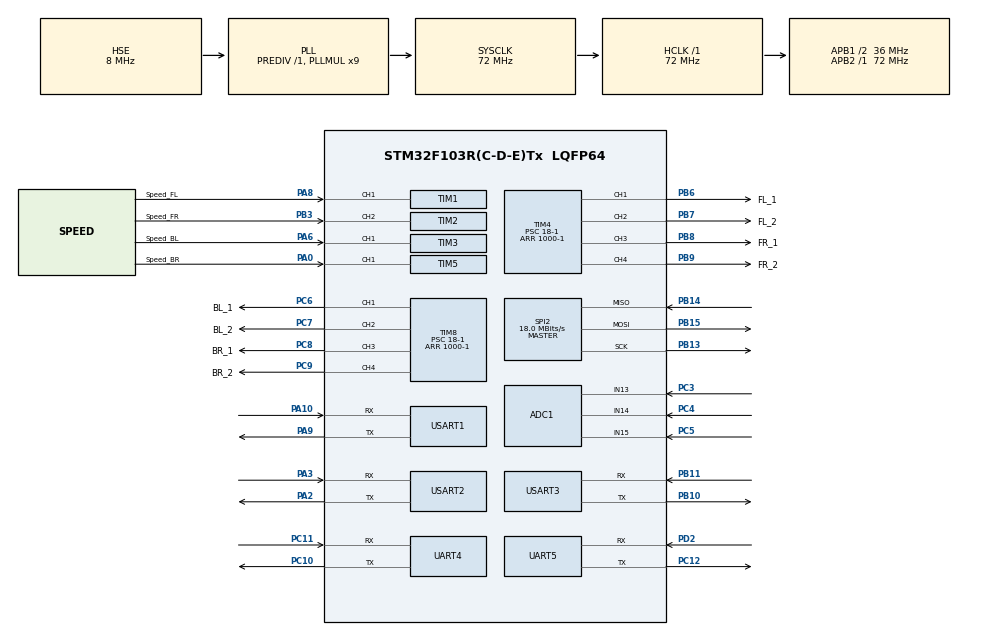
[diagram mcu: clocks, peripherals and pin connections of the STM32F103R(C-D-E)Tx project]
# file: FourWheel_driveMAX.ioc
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ADC1.Channel-0\#ChannelRegularConversion=ADC_CHANNEL_13
ADC1.NbrOfConversionFlag=1
ADC1.Rank-0\#ChannelRegularConversion=1
ADC1.SamplingTime-0\#ChannelRegularConversion=ADC_SAMPLETIME_1CYCLE_5
ADC1.master=1
Dma.Request0=UART4_TX
Dma.Request1=USART3_TX
Dma.Request2=USART2_TX
Dma.Request3=USART1_TX
Dma.UART4_TX.0.Direction=DMA_MEMORY_TO_PERIPH
Dma.UART4_TX.0.Instance=DMA2_Channel5
Dma.UART4_TX.0.MemDataAlignment=DMA_MDATAALIGN_BYTE
Dma.UART4_TX.0.MemInc=DMA_MINC_ENABLE
Dma.UART4_TX.0.Mode=DMA_NORMAL
Dma.UART4_TX.0.PeriphDataAlignment=DMA_PDATAALIGN_BYTE
Dma.UART4_TX.0.PeriphInc=DMA_PINC_DISABLE
Dma.UART4_TX.0.Priority=DMA_PRIORITY_LOW
Dma.USART1_TX.3.Direction=DMA_MEMORY_TO_PERIPH
Dma.USART1_TX.3.Instance=DMA1_Channel4
Dma.USART1_TX.3.MemDataAlignment=DMA_MDATAALIGN_BYTE
Dma.USART1_TX.3.MemInc=DMA_MINC_ENABLE
Dma.USART1_TX.3.Mode=DMA_NORMAL
Dma.USART1_TX.3.PeriphDataAlignment=DMA_PDATAALIGN_BYTE
Dma.USART1_TX.3.PeriphInc=DMA_PINC_DISABLE
Dma.USART1_TX.3.Priority=DMA_PRIORITY_LOW
Dma.USART2_TX.2.Direction=DMA_MEMORY_TO_PERIPH
Dma.USART2_TX.2.Instance=DMA1_Channel7
Dma.USART2_TX.2.MemDataAlignment=DMA_MDATAALIGN_BYTE
Dma.USART2_TX.2.MemInc=DMA_MINC_ENABLE
Dma.USART2_TX.2.Mode=DMA_NORMAL
Dma.USART2_TX.2.PeriphDataAlignment=DMA_PDATAALIGN_BYTE
Dma.USART2_TX.2.PeriphInc=DMA_PINC_DISABLE
Dma.USART2_TX.2.Priority=DMA_PRIORITY_LOW
Dma.USART3_TX.1.Direction=DMA_MEMORY_TO_PERIPH
Dma.USART3_TX.1.Instance=DMA1_Channel2
Dma.USART3_TX.1.MemDataAlignment=DMA_MDATAALIGN_BYTE
Dma.USART3_TX.1.MemInc=DMA_MINC_ENABLE
Dma.USART3_TX.1.Mode=DMA_NORMAL
Dma.USART3_TX.1.PeriphDataAlignment=DMA_PDATAALIGN_BYTE
Dma.USART3_TX.1.PeriphInc=DMA_PINC_DISABLE
Dma.USART3_TX.1.Priority=DMA_PRIORITY_LOW
IWDG.Prescaler=IWDG_PRESCALER_64
IWDG.Reload=2500
Mcu.Family=STM32F1
Mcu.Name=STM32F103R(C-D-E)Tx
Mcu.Package=LQFP64
NVIC.DMA1_Channel2_IRQn=true\:0\:0\:false\:false\:true\:false\:true
NVIC.DMA1_Channel4_IRQn=true\:0\:0\:false\:false\:true\:false\:true
NVIC.DMA1_Channel7_IRQn=true\:0\:0\:false\:false\:true\:false\:true
NVIC.DMA2_Channel4_5_IRQn=true\:0\:0\:false\:false\:true\:false\:true
NVIC.PriorityGroup=NVIC_PRIORITYGROUP_4
NVIC.TIM1_BRK_IRQn=true\:0\:0\:false\:false\:true\:true\:true
NVIC.TIM1_CC_IRQn=true\:0\:0\:false\:false\:true\:true\:true
NVIC.TIM1_TRG_COM_IRQn=true\:0\:0\:false\:false\:true\:true\:true
NVIC.TIM1_UP_IRQn=true\:0\:0\:false\:false\:true\:true\:true
NVIC.TIM2_IRQn=true\:0\:0\:false\:false\:true\:true\:true
NVIC.TIM3_IRQn=true\:0\:0\:false\:false\:true\:true\:true
NVIC.TIM4_IRQn=true\:0\:0\:false\:false\:true\:true\:true
NVIC.TIM5_IRQn=true\:0\:0\:false\:false\:true\:true\:true
NVIC.TIM6_IRQn=true\:0\:0\:false\:false\:true\:true\:true
NVIC.TIM7_IRQn=true\:0\:0\:false\:false\:true\:false\:true
NVIC.TIM8_BRK_IRQn=true\:0\:0\:false\:false\:true\:true\:true
NVIC.TIM8_CC_IRQn=true\:0\:0\:false\:false\:true\:true\:true
NVIC.TIM8_TRG_COM_IRQn=true\:0\:0\:false\:false\:true\:true\:true
NVIC.TIM8_UP_IRQn=true\:0\:0\:false\:false\:true\:true\:true
NVIC.TimeBase=TIM7_IRQn
NVIC.TimeBaseIP=TIM7
NVIC.UART4_IRQn=true\:0\:0\:false\:false\:true\:true\:true
NVIC.UART5_IRQn=true\:0\:0\:false\:false\:true\:true\:true
NVIC.USART1_IRQn=true\:0\:0\:false\:false\:true\:true\:true
NVIC.USART2_IRQn=true\:0\:0\:false\:false\:true\:true\:true
NVIC.USART3_IRQn=true\:0\:0\:false\:false\:true\:true\:true
PA0-WKUP.GPIO_Label=Speed_BR
PA0-WKUP.GPIO_PuPd=GPIO_PULLUP
PA0-WKUP.Signal=S_TIM5_CH1
PA10.Mode=Asynchronous
PA10.Signal=USART1_RX
PA13.Mode=Serial_Wire
PA13.Signal=SYS_JTMS-SWDIO
PA14.Mode=Serial_Wire
PA14.Signal=SYS_JTCK-SWCLK
PA2.Mode=Asynchronous
PA2.Signal=USART2_TX
PA3.Mode=Asynchronous
PA3.Signal=USART2_RX
PA6.GPIO_Label=Speed_BL
PA6.GPIO_PuPd=GPIO_PULLUP
PA6.Signal=S_TIM3_CH1
PA8.GPIO_Label=Speed_FL
PA8.GPIO_PuPd=GPIO_PULLUP
PA8.Signal=S_TIM1_CH1
PA9.Mode=Asynchronous
PA9.Signal=USART1_TX
PB10.Mode=Asynchronous
PB10.Signal=USART3_TX
PB11.Mode=Asynchronous
PB11.Signal=USART3_RX
PB13.Mode=Full_Duplex_Master
PB13.Signal=SPI2_SCK
PB14.Mode=Full_Duplex_Master
PB14.Signal=SPI2_MISO
PB15.Mode=Full_Duplex_Master
PB15.Signal=SPI2_MOSI
PB3.GPIO_Label=Speed_FR
PB3.GPIO_PuPd=GPIO_PULLUP
PB3.Signal=S_TIM2_CH2
PB6.GPIO_Label=FL_1
PB6.Signal=S_TIM4_CH1
PB7.GPIO_Label=FL_2
PB7.Signal=S_TIM4_CH2
PB8.GPIO_Label=FR_1
PB8.Signal=S_TIM4_CH3
PB9.GPIO_Label=FR_2
PB9.Signal=S_TIM4_CH4
PC10.Mode=Asynchronous
PC10.Signal=UART4_TX
PC11.Mode=Asynchronous
PC11.Signal=UART4_RX
PC12.Mode=Asynchronous
PC12.Signal=UART5_TX
PC3.Signal=ADCx_IN13
PC4.Signal=ADCx_IN14
PC5.Signal=ADCx_IN15
PC6.GPIO_Label=BL_1
PC6.Signal=S_TIM8_CH1
PC7.GPIO_Label=BL_2
PC7.Signal=S_TIM8_CH2
PC8.GPIO_Label=BR_1
PC8.Signal=S_TIM8_CH3
PC9.GPIO_Label=BR_2
PC9.Signal=S_TIM8_CH4
PD0-OSC_IN.Mode=HSE-External-Oscillator
PD0-OSC_IN.Signal=RCC_OSC_IN
PD1-OSC_OUT.Mode=HSE-External-Oscillator
PD1-OSC_OUT.Signal=RCC_OSC_OUT
PD2.Mode=Asynchronous
PD2.Signal=UART5_RX
ProjectManager.HeapSize=0x200
ProjectManager.StackSize=0x400
ProjectManager.TargetToolchain=MDK-ARM V5
RCC.ADCPresc=RCC_ADCPCLK2_DIV6
RCC.AHBFreq_Value=72000000
RCC.APB1CLKDivider=RCC_HCLK_DIV2
RCC.APB1Freq_Value=36000000
RCC.APB1TimFreq_Value=72000000
RCC.APB2Freq_Value=72000000
RCC.APB2TimFreq_Value=72000000
RCC.HCLKFreq_Value=72000000
RCC.PLLMUL=RCC_PLL_MUL9
RCC.PLLSourceVirtual=RCC_PLLSOURCE_HSE
RCC.SYSCLKFreq_VALUE=72000000
RCC.SYSCLKSource=RCC_SYSCLKSOURCE_PLLCLK
RCC.USBFreq_Value=72000000
SH.ADCx_IN13.0=ADC1_IN13,IN13
SH.ADCx_IN14.0=ADC1_IN14,IN14
SH.ADCx_IN15.0=ADC1_IN15,IN15
SH.S_TIM1_CH1.0=TIM1_CH1,Input_Capture1_from_TI1
SH.S_TIM2_CH2.0=TIM2_CH2,Input_Capture2_from_TI2
SH.S_TIM3_CH1.0=TIM3_CH1,Input_Capture1_from_TI1
SH.S_TIM4_CH1.0=TIM4_CH1,PWM Generation1 CH1
SH.S_TIM4_CH2.0=TIM4_CH2,PWM Generation2 CH2
SH.S_TIM4_CH3.0=TIM4_CH3,PWM Generation3 CH3
SH.S_TIM4_CH4.0=TIM4_CH4,PWM Generation4 CH4
SH.S_TIM5_CH1.0=TIM5_CH1,Input_Capture1_from_TI1
SH.S_TIM8_CH1.0=TIM8_CH1,PWM Generation1 CH1
SH.S_TIM8_CH2.0=TIM8_CH2,PWM Generation2 CH2
SH.S_TIM8_CH3.0=TIM8_CH3,PWM Generation3 CH3
SH.S_TIM8_CH4.0=TIM8_CH4,PWM Generation4 CH4
SPI2.CalculateBaudRate=18.0 MBits/s
SPI2.Direction=SPI_DIRECTION_2LINES
SPI2.Mode=SPI_MODE_MASTER
SPI2.VirtualType=VM_MASTER
TIM1.Channel-Input_Capture1_from_TI1=TIM_CHANNEL_1
TIM1.Period=0xffff
TIM1.Prescaler=0
TIM2.Channel-Input_Capture2_from_TI2=TIM_CHANNEL_2
TIM2.Period=0xffff
TIM3.Channel-Input_Capture1_from_TI1=TIM_CHANNEL_1
TIM3.Period=0xffff
TIM4.Channel-PWM\ Generation1\ CH1=TIM_CHANNEL_1
TIM4.Channel-PWM\ Generation2\ CH2=TIM_CHANNEL_2
TIM4.Channel-PWM\ Generation3\ CH3=TIM_CHANNEL_3
TIM4.Channel-PWM\ Generation4\ CH4=TIM_CHANNEL_4
TIM4.ClockDivision=TIM_CLOCKDIVISION_DIV4
TIM4.Period=1000-1
TIM4.Prescaler=18-1
TIM5.Channel-Input_Capture1_from_TI1=TIM_CHANNEL_1
TIM5.Period=0xffff
TIM6.Period=10000-1
TIM6.Prescaler=720-1
TIM8.Channel-PWM\ Generation1\ CH1=TIM_CHANNEL_1
TIM8.Channel-PWM\ Generation2\ CH2=TIM_CHANNEL_2
TIM8.Channel-PWM\ Generation3\ CH3=TIM_CHANNEL_3
TIM8.Channel-PWM\ Generation4\ CH4=TIM_CHANNEL_4
TIM8.ClockDivision=TIM_CLOCKDIVISION_DIV4
TIM8.Period=1000-1
TIM8.Prescaler=18-1
UART4.VirtualMode=Asynchronous
UART5.VirtualMode=Asynchronous
USART1.VirtualMode=VM_ASYNC
USART2.VirtualMode=VM_ASYNC
USART3.VirtualMode=VM_ASYNC
VP_IWDG_VS_IWDG.Mode=IWDG_Activate
VP_RTC_VS_RTC_Activate.Mode=RTC_Enabled
VP_SYS_VS_tim7.Mode=TIM7
VP_TIM6_VS_ClockSourceINT.Mode=Enable_Timer
board=custom

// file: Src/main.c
/* USER CODE BEGIN Header */
/**
  ******************************************************************************
  * @file           : main.c
  * @brief          : Main program body
  ******************************************************************************
  * @attention
  *
  * <h2><center>&copy; Copyright (c) 2019 STMicroelectronics.
  * All rights reserved.</center></h2>
  *
  * This software component is licensed by ST under BSD 3-Clause license,
  * the "License"; You may not use this file except in compliance with the
  * License. You may obtain a copy of the License at:

  *                        opensource.org/licenses/BSD-3-Clause
  *
  ******************************************************************************
  */
/* USER CODE END Header */

#include "main.h"
#include "adc.h"
#include "dma.h"
#include "iwdg.h"
#include "rtc.h"
#include "spi.h"
#include "tim.h"
#include "usart.h"
#include "gpio.h"

/* USER CODE BEGIN Includes */

#include "user_system.h"

/* USER CODE END Includes */

void SystemClock_Config(void);

int main(void)
{

  /* MCU Configuration--------------------------------------------------------*/

  /* Reset of all peripherals, Initializes the Flash interface and the Systick. */
  HAL_Init();

  /* Configure the system clock */
  SystemClock_Config();

  /* USER CODE BEGIN SysInit */

  /*

  /* USER CODE END SysInit */

  /* Initialize all configured peripherals */
  MX_GPIO_Init();
  MX_DMA_Init();
  MX_ADC1_Init();
  MX_IWDG_Init();
  MX_RTC_Init();
  MX_SPI2_Init();
  MX_TIM1_Init();
  MX_TIM2_Init();
  MX_TIM3_Init();
  MX_TIM4_Init();
  MX_TIM5_Init();
  MX_TIM6_Init();
  MX_TIM8_Init();
  MX_UART4_Init();
  MX_UART5_Init();
  MX_USART3_UART_Init();
  MX_USART1_UART_Init();
  MX_USART2_UART_Init();
  /* USER CODE BEGIN 2 */

	//系统初始化

	user_system_init();

  /* USER CODE END 2 */

  /* Infinite loop */
  /* USER CODE BEGIN WHILE */

  while (1)
  {

		//程序开始运行，主线程

		user_system_thread_0();

		//   看门狗·喂狗
		//		HAL_IWDG_Refresh(&hiwdg);

    /* USER CODE END WHILE */

  }
}

void SystemClock_Config(void)
{
  RCC_OscInitTypeDef RCC_OscInitStruct = {0};
  RCC_ClkInitTypeDef RCC_ClkInitStruct = {0};
  RCC_PeriphCLKInitTypeDef PeriphClkInit = {0};

  /** Initializes the CPU, AHB and APB busses clocks
  */
  RCC_OscInitStruct.OscillatorType = RCC_OSCILLATORTYPE_LSI|RCC_OSCILLATORTYPE_HSE;
  RCC_OscInitStruct.HSEState = RCC_HSE_ON;
  RCC_OscInitStruct.HSEPredivValue = RCC_HSE_PREDIV_DIV1;
  RCC_OscInitStruct.HSIState = RCC_HSI_ON;
  RCC_OscInitStruct.LSIState = RCC_LSI_ON;
  RCC_OscInitStruct.PLL.PLLState = RCC_PLL_ON;
  RCC_OscInitStruct.PLL.PLLSource = RCC_PLLSOURCE_HSE;
  RCC_OscInitStruct.PLL.PLLMUL = RCC_PLL_MUL9;
  if (HAL_RCC_OscConfig(&RCC_OscInitStruct) != HAL_OK)
  {
    Error_Handler();
  }
  /** Initializes the CPU, AHB and APB busses clocks
  */
  RCC_ClkInitStruct.ClockType = RCC_CLOCKTYPE_HCLK|RCC_CLOCKTYPE_SYSCLK
                              |RCC_CLOCKTYPE_PCLK1|RCC_CLOCKTYPE_PCLK2;
  RCC_ClkInitStruct.SYSCLKSource = RCC_SYSCLKSOURCE_PLLCLK;
  RCC_ClkInitStruct.AHBCLKDivider = RCC_SYSCLK_DIV1;
  RCC_ClkInitStruct.APB1CLKDivider = RCC_HCLK_DIV2;
  RCC_ClkInitStruct.APB2CLKDivider = RCC_HCLK_DIV1;

  if (HAL_RCC_ClockConfig(&RCC_ClkInitStruct, FLASH_LATENCY_2) != HAL_OK)
  {
    Error_Handler();
  }
  PeriphClkInit.PeriphClockSelection = RCC_PERIPHCLK_RTC|RCC_PERIPHCLK_ADC;
  PeriphClkInit.RTCClockSelection = RCC_RTCCLKSOURCE_LSI;
  PeriphClkInit.AdcClockSelection = RCC_ADCPCLK2_DIV6;
  if (HAL_RCCEx_PeriphCLKConfig(&PeriphClkInit) != HAL_OK)
  {
    Error_Handler();
  }
}

void HAL_TIM_PeriodElapsedCallback(TIM_HandleTypeDef *htim)
{
  if (htim->Instance == TIM7) {
    HAL_IncTick();
  }
}

void Error_Handler(void)
{
}

/************************ (C) COPYRIGHT STMicroelectronics *****END OF FILE****/
